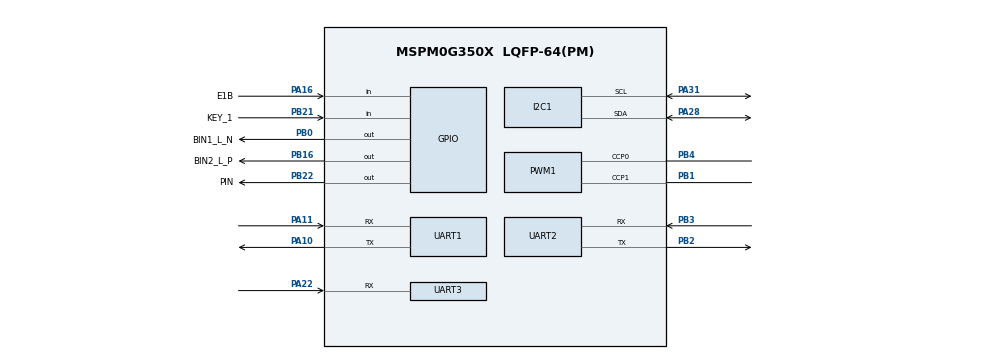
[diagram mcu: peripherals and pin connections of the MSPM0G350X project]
/**
 * @cliArgs --device "MSPM0G350X" --part "Default" --package "LQFP-64(PM)" --product "mspm0_sdk@2.02.00.05"
 * @versions {"tool":"1.21.1+3772"}
 */

/**
 * Import the modules used in this configuration.
 */
const DMA    = scripting.addModule("/ti/driverlib/DMA");
const GPIO   = scripting.addModule("/ti/driverlib/GPIO", {}, false);
const GPIO1  = GPIO.addInstance();
const GPIO2  = GPIO.addInstance();
const GPIO3  = GPIO.addInstance();
const I2C    = scripting.addModule("/ti/driverlib/I2C", {}, false);
const I2C1   = I2C.addInstance();
const PWM    = scripting.addModule("/ti/driverlib/PWM", {}, false);
const PWM1   = PWM.addInstance();
const SYSCTL = scripting.addModule("/ti/driverlib/SYSCTL");
const TIMER  = scripting.addModule("/ti/driverlib/TIMER", {}, false);
const TIMER1 = TIMER.addInstance();
const TIMER2 = TIMER.addInstance();
const TIMER3 = TIMER.addInstance();
const TIMER4 = TIMER.addInstance();
const UART   = scripting.addModule("/ti/driverlib/UART", {}, false);
const UART1  = UART.addInstance();
const UART2  = UART.addInstance();
const UART3  = UART.addInstance();

/**
 * Write custom configuration values to the imported modules.
 */
const divider9       = system.clockTree["UDIV"];
divider9.divideValue = 2;

const gate7  = system.clockTree["MFCLKGATE"];
gate7.enable = true;

const gate8  = system.clockTree["MFPCLKGATE"];
gate8.enable = true;

const multiplier2         = system.clockTree["PLL_QDIV"];
multiplier2.multiplyValue = 4;

const mux4       = system.clockTree["EXHFMUX"];
mux4.inputSelect = "EXHFMUX_XTAL";

const mux8       = system.clockTree["HSCLKMUX"];
mux8.inputSelect = "HSCLKMUX_SYSPLL0";

const mux12       = system.clockTree["SYSPLLMUX"];
mux12.inputSelect = "zSYSPLLMUX_HFCLK";

const pinFunction4        = system.clockTree["HFXT"];
pinFunction4.inputFreq    = 40;
pinFunction4.enable       = true;
pinFunction4.HFCLKMonitor = true;
pinFunction4.HFXTStartup  = 20;

const Board = scripting.addModule("/ti/driverlib/Board", {}, false);

GPIO1.$name                          = "LED";
GPIO1.associatedPins[0].$name        = "PIN";
GPIO1.associatedPins[0].ioStructure  = "SD";
GPIO1.associatedPins[0].assignedPort = "PORTB";
GPIO1.associatedPins[0].assignedPin  = "22";
GPIO1.associatedPins[0].pin.$assign  = "PB22";

GPIO2.$name                              = "KEY";
GPIO2.associatedPins.create(2);
GPIO2.associatedPins[0].$name            = "KEY_1";
GPIO2.associatedPins[0].direction        = "INPUT";
GPIO2.associatedPins[0].internalResistor = "PULL_UP";
GPIO2.associatedPins[0].pin.$assign      = "PB21";
GPIO2.associatedPins[1].$name            = "KEY_2";
GPIO2.associatedPins[1].direction        = "INPUT";
GPIO2.associatedPins[1].internalResistor = "PULL_UP";

GPIO3.$name                              = "MOTOR";
GPIO3.associatedPins.create(8);
GPIO3.associatedPins[0].$name            = "E1A";
GPIO3.associatedPins[0].assignedPort     = "PORTA";
GPIO3.associatedPins[0].assignedPin      = "15";
GPIO3.associatedPins[0].direction        = "INPUT";
GPIO3.associatedPins[0].interruptEn      = true;
GPIO3.associatedPins[0].polarity         = "RISE";
GPIO3.associatedPins[1].$name            = "E1B";
GPIO3.associatedPins[1].assignedPort     = "PORTA";
GPIO3.associatedPins[1].assignedPin      = "16";
GPIO3.associatedPins[1].direction        = "INPUT";
GPIO3.associatedPins[1].interruptEn      = true;
GPIO3.associatedPins[1].polarity         = "RISE";
GPIO3.associatedPins[1].pin.$assign      = "PA16";
GPIO3.associatedPins[2].$name            = "E2A";
GPIO3.associatedPins[2].assignedPort     = "PORTA";
GPIO3.associatedPins[2].direction        = "INPUT";
GPIO3.associatedPins[2].interruptEn      = true;
GPIO3.associatedPins[2].polarity         = "RISE";
GPIO3.associatedPins[2].assignedPin      = "17";
GPIO3.associatedPins[3].$name            = "E2B";
GPIO3.associatedPins[3].assignedPort     = "PORTA";
GPIO3.associatedPins[3].direction        = "INPUT";
GPIO3.associatedPins[3].interruptEn      = true;
GPIO3.associatedPins[3].polarity         = "RISE";
GPIO3.associatedPins[3].assignedPin      = "24";
GPIO3.associatedPins[4].assignedPort     = "PORTA";
GPIO3.associatedPins[4].assignedPin      = "13";
GPIO3.associatedPins[4].$name            = "AN1_R_P";
GPIO3.associatedPins[4].internalResistor = "PULL_UP";
GPIO3.associatedPins[5].assignedPort     = "PORTA";
GPIO3.associatedPins[5].assignedPin      = "12";
GPIO3.associatedPins[5].$name            = "AIN2_R_N";
GPIO3.associatedPins[5].internalResistor = "PULL_UP";
GPIO3.associatedPins[6].assignedPin      = "00";
GPIO3.associatedPins[6].$name            = "BIN1_L_N";
GPIO3.associatedPins[6].assignedPort     = "PORTB";
GPIO3.associatedPins[6].internalResistor = "PULL_UP";
GPIO3.associatedPins[6].pin.$assign      = "PB0";
GPIO3.associatedPins[7].assignedPin      = "16";
GPIO3.associatedPins[7].$name            = "BIN2_L_P";
GPIO3.associatedPins[7].assignedPort     = "PORTB";
GPIO3.associatedPins[7].internalResistor = "PULL_UP";
GPIO3.associatedPins[7].pin.$assign      = "PB16";

I2C1.basicEnableController             = true;
I2C1.$name                             = "I2C_OLED";
I2C1.basicControllerStandardBusSpeed   = "Fast";
I2C1.peripheral.$assign                = "I2C0";
I2C1.peripheral.sdaPin.$assign         = "PA28";
I2C1.peripheral.sclPin.$assign         = "PA31";
I2C1.sdaPinConfig.hideOutputInversion  = scripting.forceWrite(false);
I2C1.sdaPinConfig.onlyInternalResistor = scripting.forceWrite(false);
I2C1.sdaPinConfig.passedPeripheralType = scripting.forceWrite("Digital");
I2C1.sdaPinConfig.$name                = "ti_driverlib_gpio_GPIOPinGeneric4";
I2C1.sclPinConfig.hideOutputInversion  = scripting.forceWrite(false);
I2C1.sclPinConfig.onlyInternalResistor = scripting.forceWrite(false);
I2C1.sclPinConfig.passedPeripheralType = scripting.forceWrite("Digital");
I2C1.sclPinConfig.$name                = "ti_driverlib_gpio_GPIOPinGeneric5";

PWM1.$name                              = "PWM_Motor";
PWM1.timerStartTimer                    = true;
PWM1.pwmMode                            = "EDGE_ALIGN_UP";
PWM1.timerCount                         = 5000;
PWM1.peripheral.ccp0Pin.$assign         = "PB4";
PWM1.peripheral.ccp1Pin.$assign         = "PB1";
PWM1.PWM_CHANNEL_0.$name                = "ti_driverlib_pwm_PWMTimerCC0";
PWM1.PWM_CHANNEL_1.$name                = "ti_driverlib_pwm_PWMTimerCC1";
PWM1.ccp0PinConfig.direction            = scripting.forceWrite("OUTPUT");
PWM1.ccp0PinConfig.hideOutputInversion  = scripting.forceWrite(false);
PWM1.ccp0PinConfig.onlyInternalResistor = scripting.forceWrite(false);
PWM1.ccp0PinConfig.passedPeripheralType = scripting.forceWrite("Digital");
PWM1.ccp0PinConfig.$name                = "ti_driverlib_gpio_GPIOPinGeneric8";
PWM1.ccp1PinConfig.direction            = scripting.forceWrite("OUTPUT");
PWM1.ccp1PinConfig.hideOutputInversion  = scripting.forceWrite(false);
PWM1.ccp1PinConfig.onlyInternalResistor = scripting.forceWrite(false);
PWM1.ccp1PinConfig.passedPeripheralType = scripting.forceWrite("Digital");
PWM1.ccp1PinConfig.$name                = "ti_driverlib_gpio_GPIOPinGeneric9";

SYSCTL.forceDefaultClkConfig = true;
SYSCTL.clockTreeEn           = true;
SYSCTL.validateClkStatus     = true;

TIMER1.timerMode          = "PERIODIC";
TIMER1.timerClkPrescale   = 256;
TIMER1.interrupts         = ["ZERO"];
TIMER1.$name              = "TIMER_Key";
TIMER1.interruptPriority  = "3";
TIMER1.timerPeriod        = "1ms";
TIMER1.timerStartTimer    = true;
TIMER1.peripheral.$assign = "TIMA0";

TIMER2.$name              = "TIMER_1";
TIMER2.timerClkPrescale   = 100;
TIMER2.timerClkDiv        = 2;
TIMER2.interrupts         = ["ZERO"];
TIMER2.timerMode          = "PERIODIC";
TIMER2.timerStartTimer    = true;
TIMER2.timerPeriod        = "50ms";
TIMER2.peripheral.$assign = "TIMG8";

TIMER3.$name            = "TIMER_Gyro";
TIMER3.timerMode        = "PERIODIC";
TIMER3.timerStartTimer  = true;
TIMER3.timerClkPrescale = 100;
TIMER3.timerPeriod      = "20 ms";
TIMER3.interrupts       = ["ZERO"];

TIMER4.$name              = "TIMER_Pid";
TIMER4.interrupts         = ["ZERO"];
TIMER4.timerStartTimer    = true;
TIMER4.timerClkPrescale   = 40;
TIMER4.timerMode          = "PERIODIC";
TIMER4.interruptPriority  = "1";
TIMER4.timerPeriod        = "10ms";
TIMER4.peripheral.$assign = "TIMG0";

UART1.$name                    = "UART_0";
UART1.targetBaudRate           = 115200;
UART1.enabledInterrupts        = ["RX"];
UART1.enableFIFO               = true;
UART1.rxFifoThreshold          = "DL_UART_RX_FIFO_LEVEL_1_4_FULL";
UART1.peripheral.$assign       = "UART0";
UART1.peripheral.rxPin.$assign = "PA11";
UART1.peripheral.txPin.$assign = "PA10";
UART1.txPinConfig.$name        = "ti_driverlib_gpio_GPIOPinGeneric0";
UART1.rxPinConfig.$name        = "ti_driverlib_gpio_GPIOPinGeneric1";

UART2.$name                            = "UART_OPMV";
UART2.targetBaudRate                   = 115200;
UART2.enabledInterrupts                = ["RX"];
UART2.uartClkSrc                       = "MFCLK";
UART2.peripheral.rxPin.$assign         = "PB3";
UART2.peripheral.txPin.$assign         = "PB2";
UART2.txPinConfig.$name                = "ti_driverlib_gpio_GPIOPinGeneric6";
UART2.txPinConfig.direction            = scripting.forceWrite("OUTPUT");
UART2.txPinConfig.hideOutputInversion  = scripting.forceWrite(false);
UART2.txPinConfig.onlyInternalResistor = scripting.forceWrite(false);
UART2.txPinConfig.passedPeripheralType = scripting.forceWrite("Digital");
UART2.rxPinConfig.$name                = "ti_driverlib_gpio_GPIOPinGeneric7";
UART2.rxPinConfig.hideOutputInversion  = scripting.forceWrite(false);
UART2.rxPinConfig.onlyInternalResistor = scripting.forceWrite(false);
UART2.rxPinConfig.passedPeripheralType = scripting.forceWrite("Digital");

UART3.$name                            = "UART_WIT";
UART3.direction                        = "RX";
UART3.enableFIFO                       = true;
UART3.rxFifoThreshold                  = "DL_UART_RX_FIFO_LEVEL_1_4_FULL";
UART3.txFifoThreshold                  = "DL_UART_TX_FIFO_LEVEL_EMPTY";
UART3.rxTimeoutValue                   = 1;
UART3.enabledInterrupts                = ["RX_TIMEOUT_ERROR"];
UART3.enabledDMARXTriggers             = "DL_UART_DMA_INTERRUPT_RX";
UART3.targetBaudRate                   = 115200;
UART3.uartClkSrc                       = "MFCLK";
UART3.peripheral.$assign               = "UART2";
UART3.peripheral.rxPin.$assign         = "PA22";
UART3.rxPinConfig.hideOutputInversion  = scripting.forceWrite(false);
UART3.rxPinConfig.onlyInternalResistor = scripting.forceWrite(false);
UART3.rxPinConfig.passedPeripheralType = scripting.forceWrite("Digital");
UART3.rxPinConfig.$name                = "ti_driverlib_gpio_GPIOPinGeneric11";
UART3.DMA_CHANNEL_RX.$name             = "DMA_WIT";
UART3.DMA_CHANNEL_RX.srcLength         = "BYTE";
UART3.DMA_CHANNEL_RX.dstLength         = "BYTE";
UART3.DMA_CHANNEL_RX.addressMode       = "f2b";

/**
 * Pinmux solution for unlocked pins/peripherals. This ensures that minor changes to the automatic solver in a future
 * version of the tool will not impact the pinmux you originally saw.  These lines can be completely deleted in order to
 * re-solve from scratch.
 */
pinFunction4.peripheral.$suggestSolution           = "SYSCTL";
pinFunction4.peripheral.hfxInPin.$suggestSolution  = "PA5";
pinFunction4.peripheral.hfxOutPin.$suggestSolution = "PA6";
Board.peripheral.$suggestSolution                  = "DEBUGSS";
Board.peripheral.swclkPin.$suggestSolution         = "PA20";
Board.peripheral.swdioPin.$suggestSolution         = "PA19";
GPIO2.associatedPins[1].pin.$suggestSolution       = "PB13";
GPIO3.associatedPins[0].pin.$suggestSolution       = "PA15";
GPIO3.associatedPins[2].pin.$suggestSolution       = "PA17";
GPIO3.associatedPins[3].pin.$suggestSolution       = "PA24";
GPIO3.associatedPins[4].pin.$suggestSolution       = "PA13";
GPIO3.associatedPins[5].pin.$suggestSolution       = "PA12";
PWM1.peripheral.$suggestSolution                   = "TIMA1";
TIMER3.peripheral.$suggestSolution                 = "TIMG6";
UART2.peripheral.$suggestSolution                  = "UART3";
UART3.DMA_CHANNEL_RX.peripheral.$suggestSolution   = "DMA_CH0";
